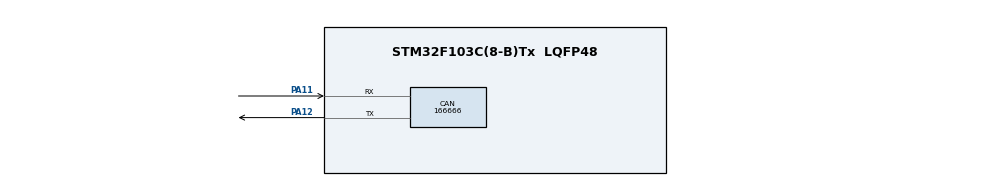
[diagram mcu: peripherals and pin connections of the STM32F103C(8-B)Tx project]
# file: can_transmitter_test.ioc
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CAN.CalculateBaudRate=166666
CAN.CalculateTimeBit=6000
CAN.CalculateTimeQuantum=2000.0
Mcu.Family=STM32F1
Mcu.Name=STM32F103C(8-B)Tx
Mcu.Package=LQFP48
NVIC.CAN1_RX1_IRQn=true\:2\:0\:true\:false\:true\:true\:true\:true
NVIC.PriorityGroup=NVIC_PRIORITYGROUP_4
PA11.Mode=CAN_Activate
PA11.Signal=CAN_RX
PA12.Mode=CAN_Activate
PA12.Signal=CAN_TX
ProjectManager.HeapSize=0x200
ProjectManager.StackSize=0x400
ProjectManager.TargetToolchain=STM32CubeIDE
RCC.APB1Freq_Value=8000000
RCC.APB2Freq_Value=8000000
board=custom

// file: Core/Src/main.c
/* USER CODE BEGIN Header */
/**
 ******************************************************************************
 * @file           : main.c
 * @brief          : Main program body
 ******************************************************************************
 * @attention
 *
 * Copyright (c) 2023 STMicroelectronics.
 * All rights reserved.
 *
 * This software is licensed under terms that can be found in the LICENSE file
 * in the root directory of this software component.
 * If no LICENSE file comes with this software, it is provided AS-IS.
 *
 ******************************************************************************
 */
/* USER CODE END Header */
#include "main.h"

/* USER CODE BEGIN Includes */
#include "stdio.h"
#include "stdlib.h"
/* USER CODE END Includes */

CAN_HandleTypeDef hcan;

void SystemClock_Config(void);
static void MX_GPIO_Init(void);
static void MX_CAN_Init(void);

/* USER CODE BEGIN 0 */
CAN_TxHeaderTypeDef TxHeader;
CAN_RxHeaderTypeDef RxHeader;

uint8_t TxData[8];
uint8_t RxData[8];

uint32_t TxMailbox;

int datacheck = 0;

void HAL_CAN_RxFifo1MsgPendingCallback(CAN_HandleTypeDef *hcan) {
	HAL_CAN_GetRxMessage(hcan, CAN_RX_FIFO1, &RxHeader, RxData);
	if (RxHeader.DLC == 2) {
		datacheck = 1;
	}
}

/* USER CODE END 0 */

int main(void) {

	/* MCU Configuration--------------------------------------------------------*/

	/* Reset of all peripherals, Initializes the Flash interface and the Systick. */
	HAL_Init();

	/* Configure the system clock */
	SystemClock_Config();

	/* Initialize all configured peripherals */
	MX_GPIO_Init();
	MX_CAN_Init();
	/* USER CODE BEGIN 2 */
	HAL_CAN_Start(&hcan);

	// Activate the notification
	HAL_CAN_ActivateNotification(&hcan, CAN_IT_RX_FIFO1_MSG_PENDING);

	TxHeader.DLC = 2;  // data length
	TxHeader.IDE = CAN_ID_STD;
	TxHeader.RTR = CAN_RTR_DATA;
	TxHeader.StdId = 0x103;  // ID

	TxData[0] = 200;  // ms delay
	TxData[1] = 20;  // loop rep
	/* USER CODE END 2 */

	/* Infinite loop */
	while (1) {
		HAL_Delay(1000);

		if (datacheck) {

			datacheck = 0;

			HAL_CAN_AddTxMessage(&hcan, &TxHeader, RxData, &TxMailbox);

		}
	}
}

void SystemClock_Config(void) {
	RCC_OscInitTypeDef RCC_OscInitStruct = { 0 };
	RCC_ClkInitTypeDef RCC_ClkInitStruct = { 0 };

	/** Initializes the RCC Oscillators according to the specified parameters
	 * in the RCC_OscInitTypeDef structure.
	 */
	RCC_OscInitStruct.OscillatorType = RCC_OSCILLATORTYPE_HSI;
	RCC_OscInitStruct.HSIState = RCC_HSI_ON;
	RCC_OscInitStruct.HSICalibrationValue = RCC_HSICALIBRATION_DEFAULT;
	RCC_OscInitStruct.PLL.PLLState = RCC_PLL_NONE;
	if (HAL_RCC_OscConfig(&RCC_OscInitStruct) != HAL_OK) {
		Error_Handler();
	}

	/** Initializes the CPU, AHB and APB buses clocks
	 */
	RCC_ClkInitStruct.ClockType = RCC_CLOCKTYPE_HCLK | RCC_CLOCKTYPE_SYSCLK
			| RCC_CLOCKTYPE_PCLK1 | RCC_CLOCKTYPE_PCLK2;
	RCC_ClkInitStruct.SYSCLKSource = RCC_SYSCLKSOURCE_HSI;
	RCC_ClkInitStruct.AHBCLKDivider = RCC_SYSCLK_DIV1;
	RCC_ClkInitStruct.APB1CLKDivider = RCC_HCLK_DIV1;
	RCC_ClkInitStruct.APB2CLKDivider = RCC_HCLK_DIV1;

	if (HAL_RCC_ClockConfig(&RCC_ClkInitStruct, FLASH_LATENCY_0) != HAL_OK) {
		Error_Handler();
	}
}

static void MX_CAN_Init(void) {

	hcan.Instance = CAN1;
	hcan.Init.Prescaler = 16;
	hcan.Init.Mode = CAN_MODE_NORMAL;
	hcan.Init.SyncJumpWidth = CAN_SJW_1TQ;
	hcan.Init.TimeSeg1 = CAN_BS1_1TQ;
	hcan.Init.TimeSeg2 = CAN_BS2_1TQ;
	hcan.Init.TimeTriggeredMode = DISABLE;
	hcan.Init.AutoBusOff = DISABLE;
	hcan.Init.AutoWakeUp = DISABLE;
	hcan.Init.AutoRetransmission = DISABLE;
	hcan.Init.ReceiveFifoLocked = DISABLE;
	hcan.Init.TransmitFifoPriority = DISABLE;
	if (HAL_CAN_Init(&hcan) != HAL_OK) {
		Error_Handler();
	}

}

static void MX_GPIO_Init(void) {

	/* GPIO Ports Clock Enable */
	__HAL_RCC_GPIOA_CLK_ENABLE();

}

/* USER CODE BEGIN 4 */
CAN_RxHeaderTypeDef RxHeader;

uint8_t RxData[8];

void HAL_CAN_RxFifo0MsgPendingCallback(CAN_HandleTypeDef *hcan) {
	if (HAL_CAN_GetRxMessage(hcan, CAN_RX_FIFO0, &RxHeader, RxData) != HAL_OK) {
		Error_Handler();
	}

	if ((RxHeader.StdId == 0x103)) {
		datacheck = 1;
	}
}
/* USER CODE END 4 */

void Error_Handler(void) {
	__disable_irq();
	while (1) {
	}
}
